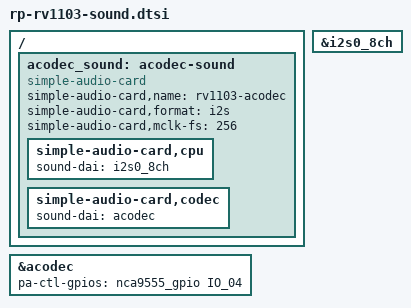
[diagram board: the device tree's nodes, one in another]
/{
    acodec_sound: acodec-sound {
        compatible = "simple-audio-card";
        simple-audio-card,name = "rv1103-acodec";
        simple-audio-card,format = "i2s";
        simple-audio-card,mclk-fs = <256>;
        simple-audio-card,cpu {
            sound-dai = <&i2s0_8ch>;
        };
        simple-audio-card,codec {
            sound-dai = <&acodec>;
        };
    };
};

&acodec {
    #sound-dai-cells = <0>;
    pa-ctl-gpios = <&nca9555_gpio IO_04 GPIO_ACTIVE_HIGH>;
    status = "okay";
};

&i2s0_8ch { 
    #sound-dai-cells = <0>;
    status = "okay";
};
